# CY8C5888LTI_LP097 register map
File version: 0.1
Registers are 8-bit, read-write, no defined reset value unless marked. A register's access mark holds for its fields unless they carry their own. Offsets are from the block's base; [hi:lo] are bit positions; {n}, {i} and the like mark numbered series; 'fields as' and 'values as' point back to an identical list.

## USBFS
Base 0x00000000
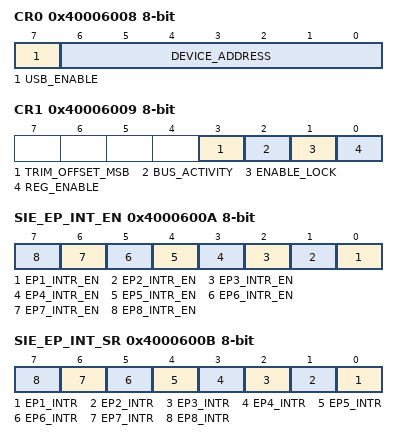
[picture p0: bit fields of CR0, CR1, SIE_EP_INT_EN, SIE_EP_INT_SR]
0x40006008 CR0 — USB Control 0 Register
  [7] USB_ENABLE — This bit enables the device to respond to USB traffic.
    0=Disabled (Block responds to USB traffic.); 1=Enabled (Block does not respond to USB traffic.)
  [6:0] DEVICE_ADDRESS ro — These bits specify the USB device address to which the SIE will respond. This address must be set by firmware and is specified by the USB Host with a SET ADDRESS command during USB enumeration. This value must be programmed by firmware when assigned during enumeration. It is not set automatically by the hardware.
0x40006009 CR1 — USB Control 1 Register
  [3] TRIM_OFFSET_MSB — This bit enables trim bit[7].
  [2] BUS_ACTIVITY — The Bus Activity bit is a stickybit that detects any non-idle USB event that has occurred on the USB bus. Once set to High by the SIE to indicate the bus activity this bit retains its logical High value until firmware clears it.
  [1] ENABLE_LOCK — This bit is set to turn on the automatic frequency locking of the internal oscillator to USB traffic. Unless an external clock is being provided this bit should remain set for proper USB operation.
  [0] REG_ENABLE ro — This bit controls the operation of the internal USB regulator. For applications with supply voltages in the 5V range this bit is set high to enable the internal regulator. For device supply voltage in the 3.3V range this bit is cleared to connect the transceiver directly to the supply.
    0=Disabled (Regulator for 5V is disabled.); 1=Enabled (Regulator for 5V is enabled.)
0x4000600A SIE_EP_INT_EN — USB SIE Data Endpoints Interrupt Enable Register
  [n-1] EP{n}_INTR_EN (n=1..8) — Enables interrupt for EP{n}.
0x4000600B SIE_EP_INT_SR — SIE Data Endpoint Interrupt Status Register
  [n-1] EP{n}_INTR (n=1..8) — Interrupt status for EP{n}.
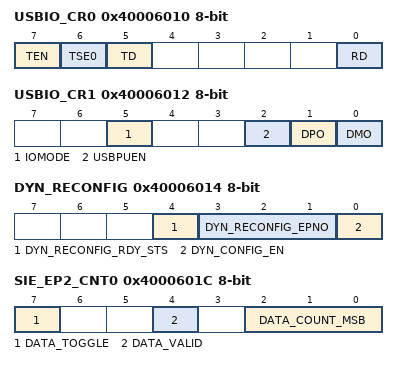
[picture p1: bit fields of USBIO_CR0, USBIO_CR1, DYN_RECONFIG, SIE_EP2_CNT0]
0x40006010 USBIO_CR0 — USBIO Control 0 Register
  [7] TEN — USB Transmit Enable. This is used to manually transmit on the D+ and D- pins. Normally this bit should be cleared to allow the internal SIE to drive the pins. The most common reason for manually transmitting is to force a resume state on the bus.
  [6] TSE0 — Transmit Single-Ended Zero. SE0: both D+ and D- low. No effect if TEN=0.
  [5] TD — Transmit Data. Transmit a USB J or K state on the USB bus. No effect if TEN=0 or TSE0=1.
    0=DIFF_K (Force USB K state (D+ is low D- is high).); 1=DIFF_J (Force USB J state (D+ is high D- is low).)
  [0] RD ro — Received Data. This read only bit gives the state of the USB differential receiver.
    0=DIFF_LOW (D+ less than D- (K state), or D+=D-=0 (SE0).); 1=DIFF_HIGH (D+ greater than D- (J state).)
0x40006012 USBIO_CR1 — USBIO Control 1 Register
  [5] IOMODE — This bit allows the D+ and D- pins to be configured for either USB mode or bit-banged modes. If this bit is set the DMI and DPI bits are used to drive the D- and D+ pins.
    0=Bit-banged mode for Dm and Dp; 1=USB (USB block controls Dm and Dp.)
  [2] USBPUEN — This bit enables the connection of the internal 1.5 k pull up resistor on the D+ pin.
  [1] DPO ro — This read only bit gives the state of the D+ pin.
  [0] DMO ro — This read only bit gives the state of the D- pin.
0x40006014 DYN_RECONFIG — USB Dynamic reconfiguration Register
  [4] DYN_RECONFIG_RDY_STS ro — This bit indicates the ready status for the dynamic reconfiguration, when set to 1, indicates the block is ready for reconfiguration.
  [3:1] DYN_RECONFIG_EPNO — These bits indicates the EP number for which reconfiguration is required when dyn_config_en bit is set to 1.
  [0] DYN_CONFIG_EN — This bit is used to enable the dynamic re-configuration for the selected EP. If set to 1, indicates the reconfiguration required for selected EP. Use 0 for EP1, 1 for EP2, etc.
0x4000601C SIE_EP2_CNT0 — SIE Endpoint 1 Count0 Register
  [7] DATA_TOGGLE — This bit selects the DATA packet's toggle state. For IN transactions firmware must set this bit to the expected state. For OUT transactions the hardware sets this bit to the state of the received Data Toggle bit.
  [4] DATA_VALID — DATA_ERROR - 0, DATA_VALID - 1.
  [2:0] DATA_COUNT_MSB — These bits are the 3 MSb bits of an 11-bit counter. The LSb are the Data Count[7:0] bits of the CNT1 register. Refer to the CNT1 register for more information.
0x4000601D SIE_EP2_CNT1 — SIE Endpoint 1 Count1 Register
  [7:0] DATA_COUNT — These bits are the 8 LSb of a 11-bit counter. The 3 MSb bits are in the CNT0 register. The 11-bit count indicates the number of data bytes in a transaction.
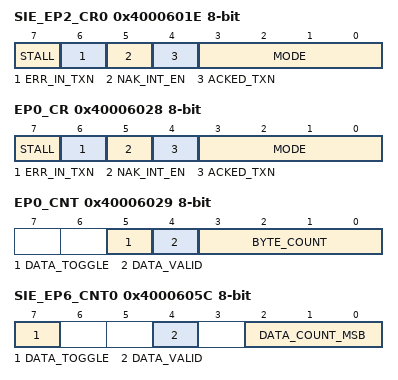
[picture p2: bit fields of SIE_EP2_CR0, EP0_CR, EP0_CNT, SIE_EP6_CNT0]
0x4000601E SIE_EP2_CR0 — SIE Endpoint 1 Control Register
  [7] STALL — When this bit is set the SIE stalls an OUT packet if the Mode bits are set to ACK-OUT. The SIE stalls an IN packet if the mode bits are set to ACK-IN. This bit must be clear for all other modes.
  [6] ERR_IN_TXN — The Error in transaction bit is set whenever an error is detected.
  [5] NAK_INT_EN — When set this bit causes an endpoint interrupt to be generated even when a transfer completes with a NAK.
  [4] ACKED_TXN — ACKED_NO - 0, ACKED_YES - 1.
  [3:0] MODE — The mode controls how the USB SIE responds to traffic and how the USB SIE changes the mode of that endpoint as a result of host packets to the endpoint.
    0=DISABLE (Ignore all USB traffic to this endpoint.); 1=NAK_INOUT (SETUP: Accept, IN: NAK, OUT: NAK.); 2=STATUS_OUT_ONLY (SETUP: Accept, IN: STALL, OUT: ACK 0B tokens, NAK others.); 3=STALL_INOUT (SETUP: Accept, IN: STALL, OUT: STALL.); 5=ISO_OUT (SETUP: Ignore, IN: Ignore, OUT: Accept Isochronous OUT token.); 6=STATUS_IN_ONLY (SETUP: Accept, IN: Respond with 0B data, OUT: Stall.); 7=ISO_IN (SETUP: Ignore, IN: Accept Isochronous IN token, OUT: Ignore.); 8=NAK_OUT (SETUP: Ignore, IN: Ignore, OUT: NAK.); 9=ACK_OUT (SETUP: Ignore, IN: Ignore, OUT: Accept data and ACK if STALL = 0, STALL otherwise. Change to MODE=8 after one succesfull OUT token.); 11=ACK_OUT_STATUS_IN (SETUP: Accept, IN: Respond with 0B data, OUT: Accept data.); 12=NAK_IN (SETUP: Ignore, IN: NAK, OUT: Ignore.); 13=ACK_IN (SETUP: Ignore, IN: Respond to IN with data if STALL=0, STALL otherwise, OUT: Ignore); 15=ACK_IN_STATUS_OUT (SETUP: Accept, IN: Respond to IN with data, OUT: ACK 0B tokens, NAK others.)
0x40006028 EP0_CR — Endpoint0 control Register
  fields as SIE_EP2_CR0
0x40006029 EP0_CNT — Endpoint0 control Register
  [5] DATA_TOGGLE — This bit selects the DATA packet's toggle state. For IN transactions firmware must set this bit to the expected state. For OUT transactions the hardware sets this bit to the state of the received Data Toggle bit.
  [4] DATA_VALID — This bit is used for OUT/SETUP transactions only and is read only. It is cleared to '0' if CRC bit stuffing errors or PID errors occur. This bit does not update for some endpoint mode settings.
    0=DATA_ERROR (No ACK'd transactions since bit was last cleared.); 1=DATA_VALID (Indicates a transaction ended with an ACK.)
  [3:0] BYTE_COUNT — These bits indicate the number of data bytes in a transaction. For IN transactions firmware loads the count with the number of bytes to be transmitted to the host from the endpoint FIFO. Valid values are 0 to 8. For OUT or SETUP transactions the count is updated by hardware to the number of data bytes received plus two for the CRC bytes. Valid values are 2 to 10.
0x4000605C SIE_EP6_CNT0 — SIE Endpoint 1 Count0 Register
  fields as SIE_EP2_CNT0
0x4000605D SIE_EP6_CNT1 — SIE Endpoint 1 Count1 Register
  fields as SIE_EP2_CNT1
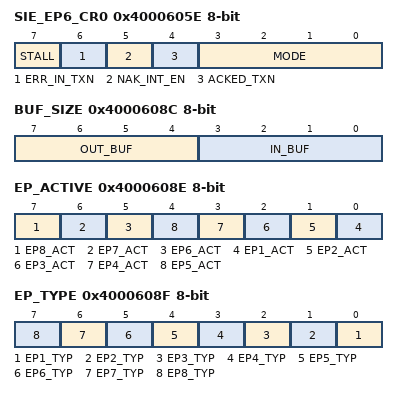
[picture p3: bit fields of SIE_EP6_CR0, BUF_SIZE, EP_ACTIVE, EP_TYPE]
0x4000605E SIE_EP6_CR0 — SIE Endpoint 1 Control Register
  fields as SIE_EP2_CR0
0x4000608C BUF_SIZE — Dedicated Endpoint Buffer Size Register
  [7:4] OUT_BUF — Buffer size for OUT Endpoints: 1 - 2 bytes, 2 - 4 bytes; 9 - 512 bytes.
  [3:0] IN_BUF — Buffer size for IN Endpoints: 1 - 2 bytes, 2 - 4 bytes; 9 - 512 bytes.
0x4000608E EP_ACTIVE — Endpoint Active Indication Register
  [7] EP8_ACT ro — Indicates that EP8 is currently active
  [6] EP7_ACT ro — Indicates that EP7 is currently active
  [5] EP6_ACT ro — Indicates that EP6 is currently active6
  [n-1] EP{n}_ACT ro (n=1..5) — Indicates that EP{n} is currently active
0x4000608F EP_TYPE — Endpoint Type (IN/OUT) Indication
  [all] fields
    0=EP_IN (IN outpoint.); 1=EP_OUT (OUT outpoint.)
  [n-1] EP{n}_TYP (n=1..8) — Endpoint Type Indication.
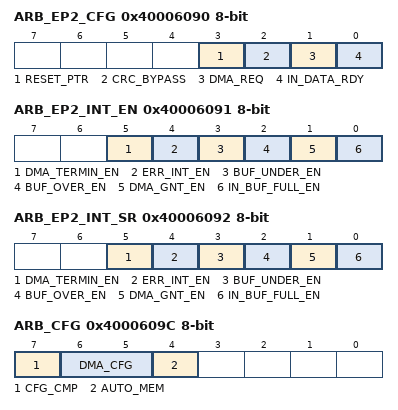
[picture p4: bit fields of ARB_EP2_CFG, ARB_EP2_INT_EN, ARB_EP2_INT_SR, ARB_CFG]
0x40006090 ARB_EP2_CFG — Arbiter Endpoint 1 Configuration Register
  [3] RESET_PTR — RESET_KRYPTON - 0, RESET_NORMAL - 1
  [2] CRC_BYPASS — CRC_NORMAL - 0, CRC_BYPASS - 1
  [1] DMA_REQ — Manual DMA Request for a particular (1 to 8) endpoint; changing this field from 0 to 1 causes a DMA request to be generated.
  [0] IN_DATA_RDY — Indication that Endpoint Packet Data is Ready in Main memory
0x40006091 ARB_EP2_INT_EN — Arbiter Endpoint 1 Interrupt Enable Register
  [5] DMA_TERMIN_EN — Endpoint DMA Terminated Enable
  [4] ERR_INT_EN — Endpoint Error in Transaction Interrupt
  [3] BUF_UNDER_EN — Endpoint Buffer Underflow
  [2] BUF_OVER_EN — Endpoint Buffer Overflow
  [1] DMA_GNT_EN — Endpoint DMA Grant
  [0] IN_BUF_FULL_EN — IN Endpoint Local Buffer Full
0x40006092 ARB_EP2_INT_SR — Arbiter Endpoint 1 Interrupt Status Register
  fields as ARB_EP2_INT_EN
0x40006094 ARB_RW2_WA — Arbiter Endpoint 1 Write Address LSB Register
  [7:0] WA8 — Write Address for EP.
0x40006095 ARB_RW2_WA_MSB — Arbiter Endpoint 1 Write Address MSB Register
  [0] WA9 — Write Address for EP MSB.
0x40006096 ARB_RW2_RA — Arbiter Endpoint 1 Read Address LSB Register
  [7:0] RA8 — Read Address for EP MSB.
0x40006097 ARB_RW2_RA_MSB — Arbiter Endpoint 1 Read Address MSB Register
  [0] RA9 — Read Address for EP MSB.
0x4000609C ARB_CFG — Arbiter configuration register
  [7] CFG_CMP — Register Configuration Complete Indication. Posedge is detected on this bit. Hence a 0 to 1 transition is required.
  [6:5] DMA_CFG — DMA Access Configuration.
    0=DMA_NONE (No DMA.); 1=DMA_MANUAL (Manual DMA.); 2=DMA_AUTO (Auto DMA.)
  [4] AUTO_MEM — Enables Auto Memory Configuration. Manual memory configuration by default.
0x4000609D USB_CLK_EN — USB Control 0 Register
  [7] CSR_CLK_EN — Clock Enable for Core Logic clocked by AHB bus clock.
    0=Disabled (Disables clock to UBS block.); 1=Enabled (Enables clock to UBS block.)
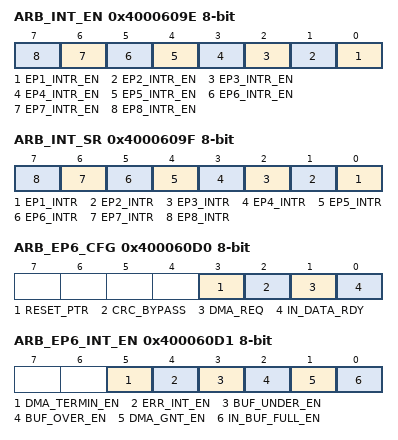
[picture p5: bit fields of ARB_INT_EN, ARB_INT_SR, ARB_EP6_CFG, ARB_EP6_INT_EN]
0x4000609E ARB_INT_EN — Arbiter Interrupt Enable Register
  [n-1] EP{n}_INTR_EN (n=1..8) — Enables interrupt for EP{n}.
0x4000609F ARB_INT_SR — Arbiter Interrupt Status
  [n-1] EP{n}_INTR ro (n=1..8) — Interrupt status for EP{n}.
0x400060AC CWA — Common Area Write Address LSB Register
  [7:0] WA8 — Write Address for Common Area.
0x400060AD CWA_MSB — Common Area Write Address LSB Register
  [0] WA9 — Write Address for Common Area MSB.
0x400060BC DMA_THRES — DMA Burst / Threshold Configuration LSB Register
  [7:0] WA8 — DMA Threshold count.
0x400060BD DMA_THRES_MSB — DMA Burst / Threshold Configuration LSB Register
  [0] WA9 — DMA Threshold count MSB.
0x400060D0 ARB_EP6_CFG — Arbiter Endpoint 1 Configuration Register
  fields as ARB_EP2_CFG
0x400060D1 ARB_EP6_INT_EN — Arbiter Endpoint 1 Interrupt Enable Register
  fields as ARB_EP2_INT_EN
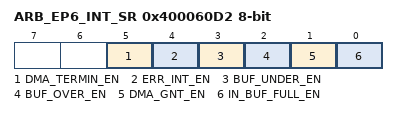
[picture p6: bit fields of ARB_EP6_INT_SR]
0x400060D2 ARB_EP6_INT_SR — Arbiter Endpoint 1 Interrupt Status Register
  fields as ARB_EP2_INT_EN
0x400060D4 ARB_RW6_WA — Arbiter Endpoint 1 Write Address LSB Register
  [7:0] WA8 — Write Address for EP.
0x400060D5 ARB_RW6_WA_MSB — Arbiter Endpoint 1 Write Address MSB Register
  [0] WA9 — Write Address for EP MSB.
0x400060D6 ARB_RW6_RA — Arbiter Endpoint 1 Read Address LSB Register
  [7:0] RA8 — Read Address for EP MSB.
0x400060D7 ARB_RW6_RA_MSB — Arbiter Endpoint 1 Read Address MSB Register
  [0] RA9 — Read Address for EP MSB.
